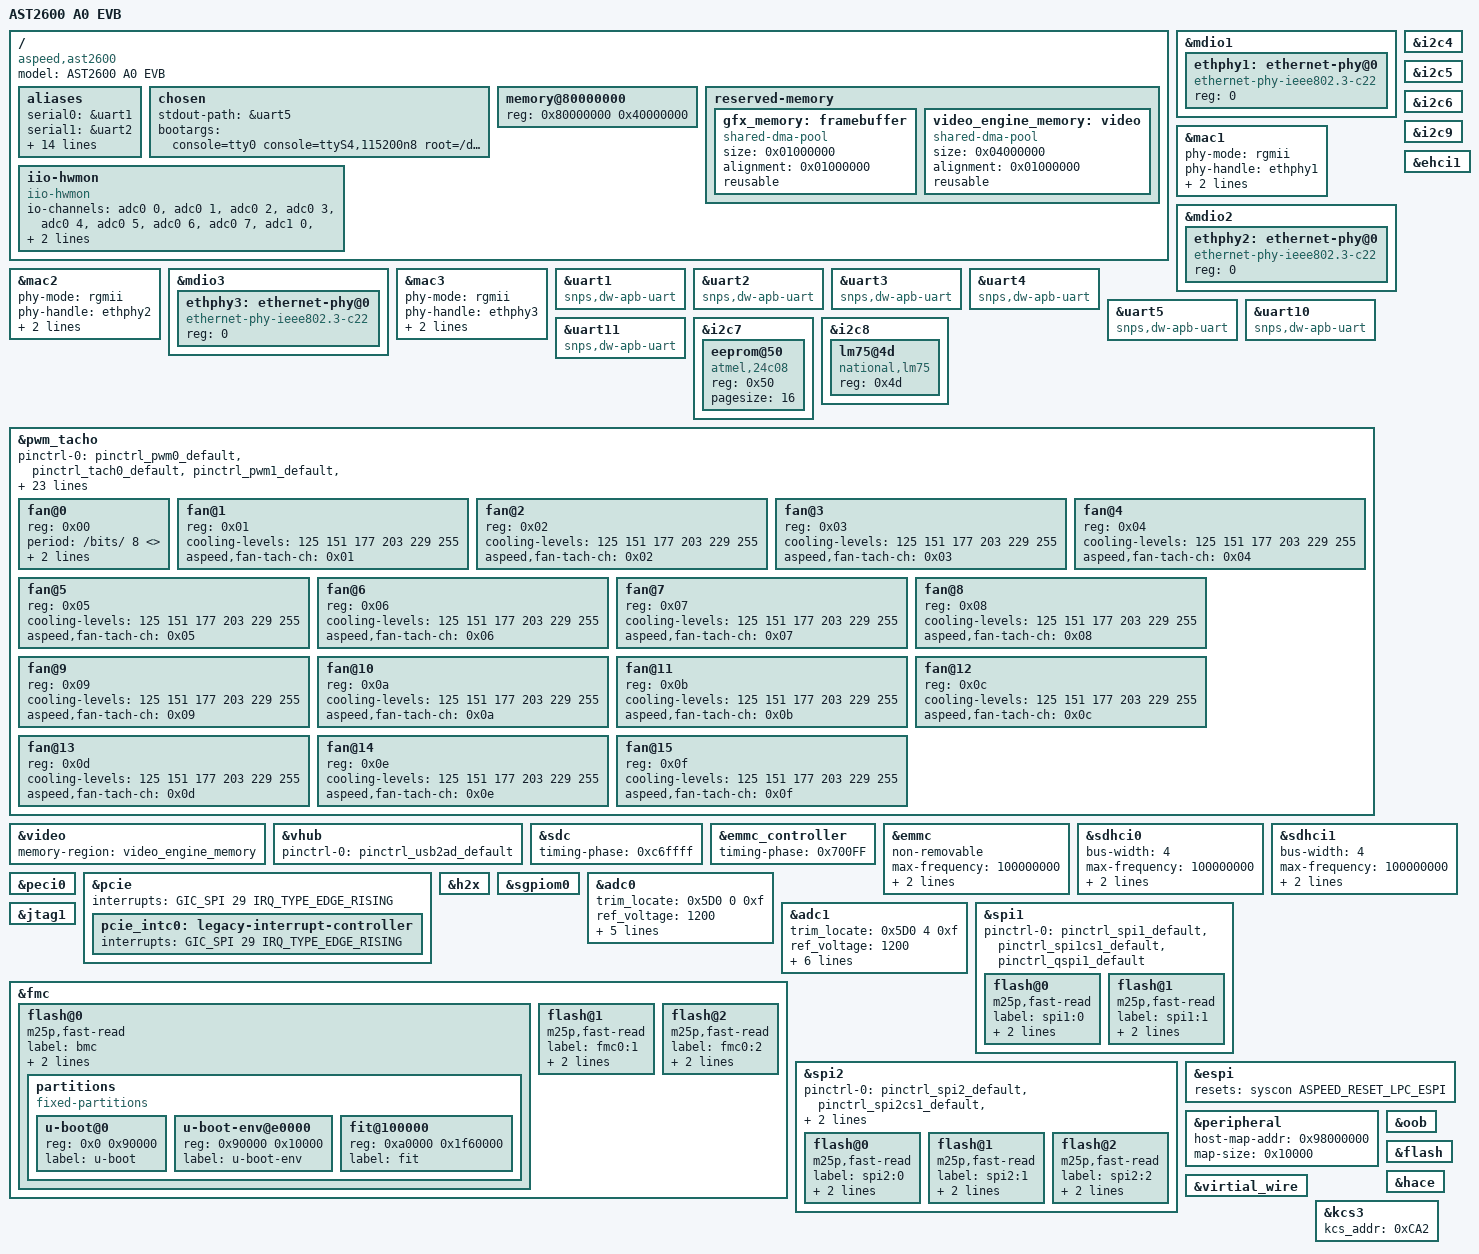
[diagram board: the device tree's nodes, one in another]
// SPDX-License-Identifier: GPL-2.0+
/dts-v1/;

#include "aspeed-g6.dtsi"

/ {
	model = "AST2600 A0 EVB";
	compatible = "aspeed,ast2600";

	aliases {
		serial0 = &uart1;
		serial1 = &uart2;
		serial2 = &uart3;
		serial3 = &uart4;
		serial4 = &uart5;
		serial5 = &uart6;
		serial6 = &uart7;
		serial7 = &uart8;
		serial8 = &uart9;
		serial9 = &uart10;
		serial10 = &uart11;
		serial11 = &uart12;
		serial12 = &uart13;
		mmc0 = &emmc;
		mmc1 = &sdhci0;
		mmc2 = &sdhci1;
	};

	chosen {
		stdout-path = &uart5;
		bootargs = "console=tty0 console=ttyS4,115200n8 root=/dev/ram rw init=/linuxrc";
	};

	memory@80000000 {
		device_type = "memory";
		reg = <0x80000000 0x40000000>;
	};

	reserved-memory {
		#address-cells = <1>;
		#size-cells = <1>;
		ranges;

		gfx_memory: framebuffer {
			size = <0x01000000>;
			alignment = <0x01000000>;
			compatible = "shared-dma-pool";
			reusable;
		};

		video_engine_memory: video {
			size = <0x04000000>;
			alignment = <0x01000000>;
			compatible = "shared-dma-pool";
			reusable;
		};
	};

	iio-hwmon {
		compatible = "iio-hwmon";
		io-channels = <&adc0 0>, <&adc0 1>, <&adc0 2>, <&adc0 3>,
				<&adc0 4>, <&adc0 5>, <&adc0 6>, <&adc0 7>,
				<&adc1 0>, <&adc1 1>, <&adc1 2>, <&adc1 3>,
				<&adc1 4>, <&adc1 5>, <&adc1 6>, <&adc1 7>;
	};	
};


&mdio1 {
	status = "okay";

	ethphy1: ethernet-phy@0 {
		compatible = "ethernet-phy-ieee802.3-c22";
		reg = <0>;
	};
};

&mac1 {
	status = "okay";

	phy-mode = "rgmii";
	phy-handle = <&ethphy1>;

	pinctrl-names = "default";
	pinctrl-0 = <&pinctrl_rgmii2_default &pinctrl_maclink2_default>;
};

&mdio2 {
	status = "okay";

	ethphy2: ethernet-phy@0 {
		compatible = "ethernet-phy-ieee802.3-c22";
		reg = <0>;
	};
};

&mac2 {
	status = "okay";

	phy-mode = "rgmii";
	phy-handle = <&ethphy2>;

	pinctrl-names = "default";
	pinctrl-0 = <&pinctrl_rgmii3_default &pinctrl_maclink3_default>;
};

&mdio3 {
	status = "okay";

	ethphy3: ethernet-phy@0 {
		compatible = "ethernet-phy-ieee802.3-c22";
		reg = <0>;
	};
};

&mac3 {
	status = "okay";

	phy-mode = "rgmii";
	phy-handle = <&ethphy3>;

	pinctrl-names = "default";
	pinctrl-0 = <&pinctrl_rgmii4_default &pinctrl_maclink4_default>;
};

&uart1 {
	// A0 workaround for UART devices
	compatible = "snps,dw-apb-uart";
	status = "okay";
};

&uart2 {
	compatible = "snps,dw-apb-uart";
	status = "okay";
};

&uart3 {
	compatible = "snps,dw-apb-uart";
	status = "okay";
};

&uart4 {
	compatible = "snps,dw-apb-uart";
	status = "okay";
};

&uart5 {
	compatible = "snps,dw-apb-uart";
	status = "okay";
};

&uart10 {
	compatible = "snps,dw-apb-uart";
	status = "okay";
};

&uart11 {
	compatible = "snps,dw-apb-uart";
	status = "okay";
};

&i2c4 {
	status = "okay";
};

&i2c5 {
	status = "okay";
};

&i2c6 {
	status = "okay";
};

&i2c7 {
	status = "okay";

	eeprom@50 {
		compatible = "atmel,24c08";
		reg = <0x50>;
		pagesize = <16>;
	};

};

&i2c8 {
	status = "okay";

	lm75@4d {
		compatible = "national,lm75";
		reg = <0x4d>;
	};

};

&i2c9 {
	status = "okay";
};


&pwm_tacho {
	status = "okay";
	pinctrl-names = "default";
	pinctrl-0 = <&pinctrl_pwm0_default &pinctrl_tach0_default 
			&pinctrl_pwm1_default &pinctrl_tach1_default
			&pinctrl_pwm2_default &pinctrl_tach2_default
			&pinctrl_pwm3_default &pinctrl_tach3_default
			&pinctrl_pwm4_default &pinctrl_tach4_default
			&pinctrl_pwm5_default &pinctrl_tach5_default
			&pinctrl_pwm6_default &pinctrl_tach6_default
			&pinctrl_pwm7_default &pinctrl_tach7_default
			&pinctrl_pwm8g1_default &pinctrl_tach8_default
			&pinctrl_pwm9g1_default &pinctrl_tach9_default
			&pinctrl_pwm10g1_default &pinctrl_tach10_default
			&pinctrl_pwm11g1_default &pinctrl_tach11_default
			&pinctrl_pwm12g1_default &pinctrl_tach12_default
			&pinctrl_pwm13g1_default &pinctrl_tach13_default
			&pinctrl_pwm14g1_default &pinctrl_tach14_default
			&pinctrl_pwm15g1_default &pinctrl_tach15_default>;

	fan@0 {
		reg = <0x00>;
		period = /bits/ 8 <>;
		cooling-levels = /bits/ 8 <125 151 177 203 229 255>;
		aspeed,fan-tach-ch = /bits/ 8 <0x00>;
	};

	fan@1 {
		reg = <0x01>;
		cooling-levels = /bits/ 8 <125 151 177 203 229 255>;
		aspeed,fan-tach-ch = /bits/ 8 <0x01>;
	};

	fan@2 {
		reg = <0x02>;
		cooling-levels = /bits/ 8 <125 151 177 203 229 255>;
		aspeed,fan-tach-ch = /bits/ 8 <0x02>;
	};

	fan@3 {
		reg = <0x03>;
		cooling-levels = /bits/ 8 <125 151 177 203 229 255>;
		aspeed,fan-tach-ch = /bits/ 8 <0x03>;
	};

	fan@4 {
		reg = <0x04>;
		cooling-levels = /bits/ 8 <125 151 177 203 229 255>;
		aspeed,fan-tach-ch = /bits/ 8 <0x04>;
	};

	fan@5 {
		reg = <0x05>;
		cooling-levels = /bits/ 8 <125 151 177 203 229 255>;
		aspeed,fan-tach-ch = /bits/ 8 <0x05>;
	};

	fan@6 {
		reg = <0x06>;
		cooling-levels = /bits/ 8 <125 151 177 203 229 255>;
		aspeed,fan-tach-ch = /bits/ 8 <0x06>;
	};

	fan@7 {
		reg = <0x07>;
		cooling-levels = /bits/ 8 <125 151 177 203 229 255>;
		aspeed,fan-tach-ch = /bits/ 8 <0x07>;
	};

	fan@8 {
		reg = <0x08>;
		cooling-levels = /bits/ 8 <125 151 177 203 229 255>;
		aspeed,fan-tach-ch = /bits/ 8 <0x08>;
	};

	fan@9 {
		reg = <0x09>;
		cooling-levels = /bits/ 8 <125 151 177 203 229 255>;
		aspeed,fan-tach-ch = /bits/ 8 <0x09>;
	};

	fan@10 {
		reg = <0x0a>;
		cooling-levels = /bits/ 8 <125 151 177 203 229 255>;
		aspeed,fan-tach-ch = /bits/ 8 <0x0a>;
	};

	fan@11 {
		reg = <0x0b>;
		cooling-levels = /bits/ 8 <125 151 177 203 229 255>;
		aspeed,fan-tach-ch = /bits/ 8 <0x0b>;
	};

	fan@12 {
		reg = <0x0c>;
		cooling-levels = /bits/ 8 <125 151 177 203 229 255>;
		aspeed,fan-tach-ch = /bits/ 8 <0x0c>;
	};

	fan@13 {
		reg = <0x0d>;
		cooling-levels = /bits/ 8 <125 151 177 203 229 255>;
		aspeed,fan-tach-ch = /bits/ 8 <0x0d>;
	};

	fan@14 {
		reg = <0x0e>;
		cooling-levels = /bits/ 8 <125 151 177 203 229 255>;
		aspeed,fan-tach-ch = /bits/ 8 <0x0e>;
	};

	fan@15 {
		reg = <0x0f>;
		cooling-levels = /bits/ 8 <125 151 177 203 229 255>;
		aspeed,fan-tach-ch = /bits/ 8 <0x0f>;
	};
};

&video {
	status = "okay";
	memory-region = <&video_engine_memory>;
};

&vhub {
	status = "okay";
	pinctrl-names = "default";
#if 1
	pinctrl-0 = <&pinctrl_usb2ad_default>;
#else
	pinctrl-0 = <&pinctrl_usb2adp_default>;
#endif
};

#if 0
&ehci0 {
	status = "okay";
};
#endif

&ehci1 {
	status = "okay";
};

&sdc {
	status = "okay";
	timing-phase = <0xc6ffff>;
};

&emmc_controller {
	status = "okay";
	timing-phase = <0x700FF>;
};

&emmc {
	status = "okay";

	non-removable;
	max-frequency = <100000000>;
	/* AST2600 A0 only support PIO mode */
	sdhci-caps-mask = <0x0 0x580000>;
#if 1
	bus-width = <4>;
#else
	bus-width = <8>;
	pinctrl-0 = <&pinctrl_emmc_default 
			&pinctrl_emmcdat4_default 
			&pinctrl_emmcdat5_default
			&pinctrl_emmcdat6_default
			&pinctrl_emmcdat7_default>;
#endif
};

&sdhci0 {
	status = "okay";

	bus-width = <4>;
	max-frequency = <100000000>;

	/* SDR104/DDR50/SDR50 bits in CAPA2 is not supported */
	sdhci-caps-mask = <0x7 0x0>;
	sdhci,wp-inverted;
};

&sdhci1 {
	status = "okay";

	bus-width = <4>;
	max-frequency = <100000000>;
	sdhci-caps-mask = <0x7 0x0>;
	sdhci,wp-inverted;
};

&peci0 {
	status = "okay";
};

&pcie {
	status = "okay";

	interrupts = <GIC_SPI 29 IRQ_TYPE_EDGE_RISING>;

	pcie_intc0: legacy-interrupt-controller {
		interrupts = <GIC_SPI 29 IRQ_TYPE_EDGE_RISING>;
	};
};

&h2x {
	status = "okay";
};

&sgpiom0 {
        status = "okay";
};

&adc0 {
	trim_locate = <0x5D0 0 0xf>;
	ref_voltage = <1200>;
	status = "okay";

	pinctrl-0 = <&pinctrl_adc0_default &pinctrl_adc1_default
		&pinctrl_adc2_default &pinctrl_adc3_default
		&pinctrl_adc4_default &pinctrl_adc5_default
		&pinctrl_adc6_default &pinctrl_adc7_default>;
};

&adc1 {
	trim_locate = <0x5D0 4 0xf>;
	ref_voltage = <1200>;
	status = "okay";

	pinctrl-0 = <&pinctrl_adc8_default &pinctrl_adc9_default
		&pinctrl_adc10_default &pinctrl_adc11_default
		&pinctrl_adc12_default &pinctrl_adc13_default
		&pinctrl_adc14_default &pinctrl_adc15_default>;
};

&jtag1 {
	status = "okay";
};
#if 1
&fmc {
	status = "okay";

	flash@0 {
		status = "okay";
		m25p,fast-read;
		label = "bmc";
		spi-max-frequency = <50000000>;
		spi-bus-width = <4>;

		partitions {
			compatible = "fixed-partitions";
			#address-cells = <1>;
			#size-cells = <1>;

			u-boot@0 {
				reg = <0x0 0x90000>;
				label = "u-boot";
			};

			u-boot-env@e0000 {
				reg = <0x90000 0x10000>; 
				label = "u-boot-env";
			};

			fit@100000 {
				reg = <0xa0000 0x1f60000>;
				label = "fit";
			};

		};
	};

	flash@1 {
		status = "okay";
		m25p,fast-read;
		label = "fmc0:1";
		spi-max-frequency = <50000000>;
		spi-bus-width = <4>;
	};

	flash@2 {
		status = "okay";
		m25p,fast-read;
		label = "fmc0:2";
		spi-max-frequency = <50000000>;
		spi-bus-width = <4>;
	};

};
#else
&fmc {
        status = "okay";
        flash: m25p80@0 {
        compatible = "mx25l25635e", "m25p80", "jedec,spi-nor";
        reg = <0x0>;
        #address-cells = <0x1>;
        #size-cells = <0x1>;
        spi-max-frequency = <50000000>;
        m25p,fast-read;
                partition@0 {
                        label = "all.bin 8MB";
                        reg = <0x000000 0x0800000>; /* 8 MiB */
                };
                partition@1 {
                        label = "u-boot";
                        reg = <0x000000 0x060000>; /* 384 KiB */
                };
                partition@2 {
                        label = "u-boot-env";
                        reg = <0x060000 0x010000>; /* 64 KiB */
                };
                partition@3 {
                        label = "dts";
                        reg = <0x070000 0x010000>; /* 64 Kib */
                };
                partition@4 {
                        label = "kernel";
                        reg = <0x080000 0x380000>; /* 3.5 MiB */
                };
                partition@5 {
                        label = "rootfs";
                        reg = <0x400000 0x400000>; /* 4 MiB */
                };
                partition@6 {
                        label = "pd_rootfs";
                        reg = <0x800000 0x0>;
                };
        };
};

#endif
&spi1 {
	status = "okay";

	pinctrl-names = "default";
	pinctrl-0 = <&pinctrl_spi1_default &pinctrl_spi1cs1_default &pinctrl_qspi1_default>;

	flash@0 {
		status = "okay";
		m25p,fast-read;
		label = "spi1:0";
		spi-max-frequency = <50000000>;
		spi-bus-width = <4>;
	};

	flash@1 {
		status = "okay";
		m25p,fast-read;
		label = "spi1:1";
		spi-max-frequency = <50000000>;
		spi-bus-width = <4>;
	};
};

&spi2 {
	status = "okay";

	pinctrl-names = "default";
	pinctrl-0 = <&pinctrl_spi2_default &pinctrl_spi2cs1_default &pinctrl_spi2cs2_default
				&pinctrl_qspi2_default>;

	flash@0 {
		status = "okay";
		m25p,fast-read;
		label = "spi2:0";
		spi-max-frequency = <50000000>;
		spi-bus-width = <4>;
	};

	flash@1 {
		status = "okay";
		m25p,fast-read;
		label = "spi2:1";
		spi-max-frequency = <50000000>;
		spi-bus-width = <4>;
	};

	flash@2 {
		status = "okay";
		m25p,fast-read;
		label = "spi2:2";
		spi-max-frequency = <50000000>;
		spi-bus-width = <4>;
	};

};

&espi {
	status = "okay";
	
	resets = <&syscon ASPEED_RESET_LPC_ESPI>;
	
};

&peripheral {
	status = "okay";
	host-map-addr = <0x98000000>;
	map-size = <0x10000>;
};

&virtial_wire {
	status = "okay";
};

&oob {
	status = "okay";
};

&flash {
	status = "okay";
};

&hace {
	status = "okay";
};

&kcs3 {
	kcs_addr = <0xCA2>;
	status = "okay";
};
